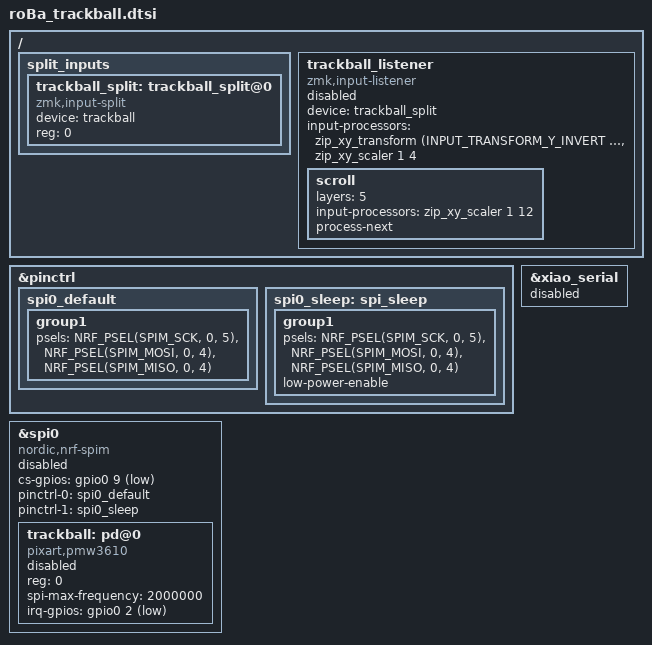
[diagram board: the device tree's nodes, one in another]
/*
 * Copyright (c) 2020 Pete Johanson
 *
 * SPDX-License-Identifier: MIT
 */
#include <zephyr/dt-bindings/input/input-event-codes.h>

#define INPUT_EV_KEY 0x01               /**< Key event */
#define INPUT_EV_REL 0x02               /**< Relative coordinate event */
#define INPUT_EV_ABS 0x03               /**< Absolute coordinate event */
#define INPUT_EV_MSC 0x04               /**< Miscellaneous event */
#define INPUT_EV_VENDOR_START 0xf0      /**< Vendor specific event start */
#define INPUT_EV_VENDOR_STOP 0xff       /**< Vendor specific event stop */
#define INPUT_REL_X 0x00                /**< Relative X coordinate */
#define INPUT_REL_Y 0x01                /**< Relative Y coordinate */
#define INPUT_REL_WHEEL 0x08            /**< Relative wheel coordinate */
#define INPUT_REL_HWHEEL 0x06           /**< Relative horizontal wheel coordinate */
#define INPUT_REL_MISC 0x09             /**< Relative misc coordinate */

&pinctrl {
    spi0_default: spi0_default {
        group1 {
            psels = <NRF_PSEL(SPIM_SCK, 0, 5)>,
                <NRF_PSEL(SPIM_MOSI, 0, 4)>,
                <NRF_PSEL(SPIM_MISO, 0, 4)>;
        };
    };

    spi0_sleep: spi_sleep {
        group1 {
            psels = <NRF_PSEL(SPIM_SCK, 0, 5)>,
                <NRF_PSEL(SPIM_MOSI, 0, 4)>,
                <NRF_PSEL(SPIM_MISO, 0, 4)>;
            low-power-enable;
        };
    };
};

&spi0 {
    status = "disabled";
    cs-gpios = <&gpio0 9 GPIO_ACTIVE_LOW>;
    pinctrl-0 = <&spi0_default>;
    pinctrl-1 = <&spi0_sleep>;
    pinctrl-names = "default", "sleep";
    compatible = "nordic,nrf-spim";

    trackball: pd@0 {
        status = "disabled";
        compatible = "pixart,pmw3610";
        reg = <0>;
        spi-max-frequency = <2000000>;
        irq-gpios = <&gpio0 2 (GPIO_ACTIVE_LOW | GPIO_PULL_UP)>;
    };
};



/ {
    split_inputs {
        #address-cells = <1>;
        #size-cells = <0>;

        trackball_split: trackball_split@0 {
            device = <&trackball>;
            compatible = "zmk,input-split";
            reg = <0>;
        };
    };

    trackball_listener: trackball_listener {
    compatible = "zmk,input-listener";
    status = "disabled";
    device = <&trackball_split>;
    input-processors = <&zip_xy_transform (INPUT_TRANSFORM_Y_INVERT | INPUT_TRANSFORM_X_INVERT | INPUT_TRANSFORM_XY_SWAP)>, <&zip_xy_scaler 1 4>;

    scroll {
      layers = <5>;
      input-processors = <&zip_xy_scaler 1 12>;
      process-next;
    };
  };
};

&xiao_serial { status = "disabled"; };







